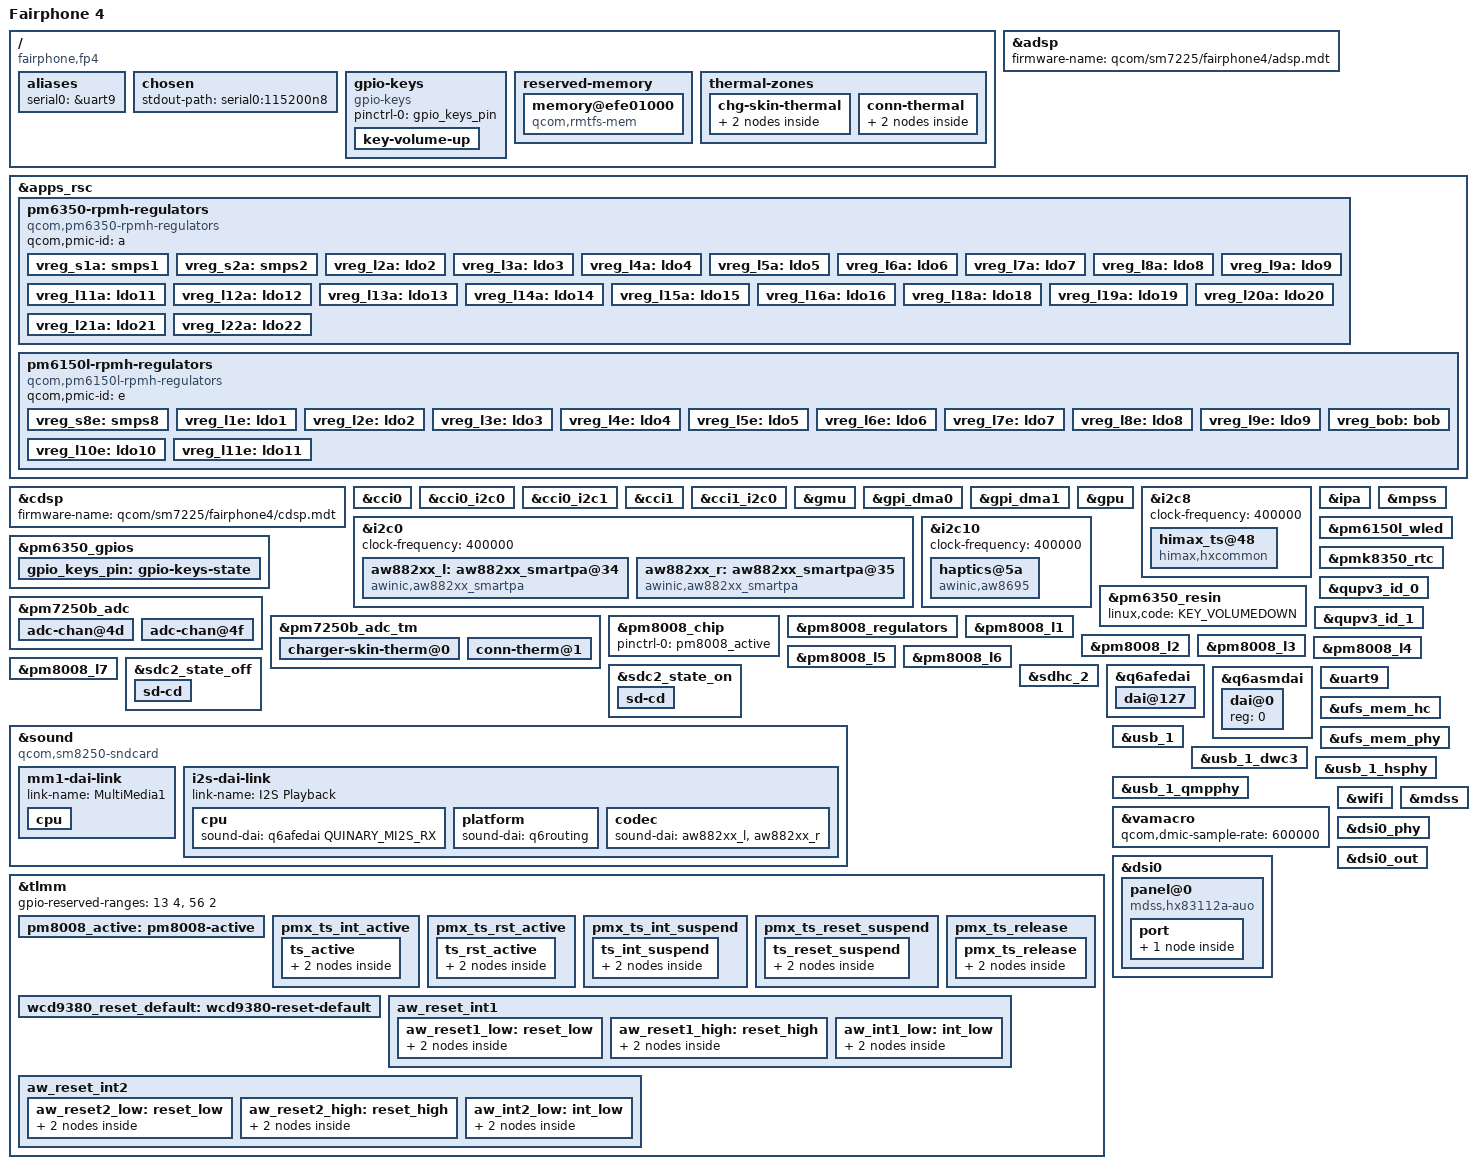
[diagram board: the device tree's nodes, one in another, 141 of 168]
// SPDX-License-Identifier: BSD-3-Clause
/*
 * Copyright (c) 2021, Luca Weiss <luca@z3ntu.xyz>
 */

/dts-v1/;

#include <dt-bindings/gpio/gpio.h>
#include <dt-bindings/input/input.h>
#include <dt-bindings/pinctrl/qcom,pmic-gpio.h>
#include <dt-bindings/regulator/qcom,rpmh-regulator.h>
#include <dt-bindings/sound/qcom,q6asm.h>
#include "sm7225.dtsi"
#include "pm6150l.dtsi"
#include "pm6350.dtsi"
#include "pm7250b.dtsi"
#include "pmk8350.dtsi"

/ {
	model = "Fairphone 4";
	compatible = "fairphone,fp4", "qcom,sm7225";
	chassis-type = "handset";

	/* required for bootloader to select correct board */
	qcom,msm-id = <434 0x10000>, <459 0x10000>;
	qcom,board-id = <8 32>;

	aliases {
		serial0 = &uart9;
	};

	chosen {
		#address-cells = <2>;
		#size-cells = <2>;
		ranges;

		stdout-path = "serial0:115200n8";
	};

#if 0
	wcd9380: codec {
		compatible = "qcom,wcd9380-codec";
		#sound-dai-cells = <1>;
		reset-gpios = <&tlmm 83 GPIO_ACTIVE_HIGH>;
		vdd-buck-supply = <&vreg_l14a>;
		vdd-rxtx-supply = <&vreg_l11a>;
		vdd-io-supply = <&vreg_l11a>;
		vdd-mic-bias-supply = <&vreg_bob>;
		qcom,micbias1-microvolt = <2700000>;
		qcom,micbias2-microvolt = <2700000>;
		qcom,micbias3-microvolt = <2700000>;
		qcom,micbias4-microvolt = <2700000>;
		//qcom,mbhc-buttons-vthreshold-microvolt = <75000 150000 237000 500000 500000 500000 500000 500000>;
		//qcom,mbhc-headset-vthreshold-microvolt = <1700000>;
		//qcom,mbhc-headphone-vthreshold-microvolt = <50000>;
		qcom,rx-device = <&wcd_rx>;
		qcom,tx-device = <&wcd_tx>;

		pinctrl-names = "default";
		pinctrl-0 = <&wcd9380_reset_default>;
	};
#endif

	gpio-keys {
		compatible = "gpio-keys";
		pinctrl-names = "default";
		pinctrl-0 = <&gpio_keys_pin>;

		key-volume-up {
			label = "volume_up";
			linux,code = <KEY_VOLUMEUP>;
			gpios = <&pm6350_gpios 2 GPIO_ACTIVE_LOW>;
		};
	};

	reserved-memory {
		/*
		 * The rmtfs memory region in downstream is 'dynamically allocated'
		 * but given the same address every time. Hard code it as this address is
		 * where the modem firmware expects it to be.
		 */
		memory@efe01000 {
			compatible = "qcom,rmtfs-mem";
			reg = <0 0xefe01000 0 0x600000>;
			no-map;

			qcom,client-id = <1>;
			qcom,vmid = <15>;
		};
	};

	thermal-zones {
		chg-skin-thermal {
			polling-delay-passive = <0>;
			polling-delay = <0>;
			thermal-sensors = <&pm7250b_adc_tm 0>;

			trips {
				active-config0 {
					temperature = <125000>;
					hysteresis = <1000>;
					type = "passive";
				};
			};
		};

		conn-thermal {
			polling-delay-passive = <0>;
			polling-delay = <0>;
			thermal-sensors = <&pm7250b_adc_tm 1>;

			trips {
				active-config0 {
					temperature = <125000>;
					hysteresis = <1000>;
					type = "passive";
				};
			};
		};
	};
};

&adsp {
	status = "okay";
	firmware-name = "qcom/sm7225/fairphone4/adsp.mdt";
};

&apps_rsc {
	pm6350-rpmh-regulators {
		compatible = "qcom,pm6350-rpmh-regulators";
		qcom,pmic-id = "a";

		vreg_s1a: smps1 {
			regulator-min-microvolt = <1000000>;
			regulator-max-microvolt = <1200000>;
		};

		vreg_s2a: smps2 {
			regulator-min-microvolt = <1503000>;
			regulator-max-microvolt = <2048000>;
		};

		vreg_l2a: ldo2 {
			regulator-min-microvolt = <1503000>;
			regulator-max-microvolt = <1980000>;
			regulator-initial-mode = <RPMH_REGULATOR_MODE_HPM>;
		};

		vreg_l3a: ldo3 {
			regulator-min-microvolt = <2700000>;
			regulator-max-microvolt = <3300000>;
			regulator-initial-mode = <RPMH_REGULATOR_MODE_HPM>;
		};

		vreg_l4a: ldo4 {
			regulator-min-microvolt = <352000>;
			regulator-max-microvolt = <801000>;
			regulator-initial-mode = <RPMH_REGULATOR_MODE_HPM>;
		};

		vreg_l5a: ldo5 {
			regulator-min-microvolt = <1503000>;
			regulator-max-microvolt = <1980000>;
			regulator-initial-mode = <RPMH_REGULATOR_MODE_HPM>;
		};

		vreg_l6a: ldo6 {
			regulator-min-microvolt = <1710000>;
			regulator-max-microvolt = <3544000>;
			regulator-initial-mode = <RPMH_REGULATOR_MODE_HPM>;
		};

		vreg_l7a: ldo7 {
			regulator-min-microvolt = <1620000>;
			regulator-max-microvolt = <1980000>;
			regulator-initial-mode = <RPMH_REGULATOR_MODE_HPM>;
		};

		vreg_l8a: ldo8 {
			regulator-min-microvolt = <2800000>;
			regulator-max-microvolt = <2800000>;
			regulator-initial-mode = <RPMH_REGULATOR_MODE_HPM>;
		};

		vreg_l9a: ldo9 {
			regulator-min-microvolt = <1650000>;
			regulator-max-microvolt = <3401000>;
			regulator-initial-mode = <RPMH_REGULATOR_MODE_HPM>;
		};

		vreg_l11a: ldo11 {
			regulator-min-microvolt = <1800000>;
			regulator-max-microvolt = <2000000>;
			regulator-initial-mode = <RPMH_REGULATOR_MODE_HPM>;
			regulator-always-on;
		};

		vreg_l12a: ldo12 {
			regulator-min-microvolt = <1620000>;
			regulator-max-microvolt = <1980000>;
			regulator-initial-mode = <RPMH_REGULATOR_MODE_HPM>;
		};

		vreg_l13a: ldo13 {
			regulator-min-microvolt = <570000>;
			regulator-max-microvolt = <650000>;
			regulator-initial-mode = <RPMH_REGULATOR_MODE_HPM>;
		};

		vreg_l14a: ldo14 {
			regulator-min-microvolt = <1700000>;
			regulator-max-microvolt = <1900000>;
			regulator-initial-mode = <RPMH_REGULATOR_MODE_HPM>;
		};

		vreg_l15a: ldo15 {
			regulator-min-microvolt = <1100000>;
			regulator-max-microvolt = <1305000>;
			regulator-initial-mode = <RPMH_REGULATOR_MODE_HPM>;
		};

		vreg_l16a: ldo16 {
			regulator-min-microvolt = <830000>;
			regulator-max-microvolt = <921000>;
			regulator-initial-mode = <RPMH_REGULATOR_MODE_HPM>;
		};

		vreg_l18a: ldo18 {
			regulator-min-microvolt = <788000>;
			regulator-max-microvolt = <1049000>;
			regulator-initial-mode = <RPMH_REGULATOR_MODE_HPM>;
		};

		vreg_l19a: ldo19 {
			regulator-min-microvolt = <1080000>;
			regulator-max-microvolt = <1305000>;
			regulator-initial-mode = <RPMH_REGULATOR_MODE_HPM>;
		};

		vreg_l20a: ldo20 {
			regulator-min-microvolt = <530000>;
			regulator-max-microvolt = <801000>;
			regulator-initial-mode = <RPMH_REGULATOR_MODE_HPM>;
		};

		vreg_l21a: ldo21 {
			regulator-min-microvolt = <751000>;
			regulator-max-microvolt = <825000>;
			regulator-initial-mode = <RPMH_REGULATOR_MODE_HPM>;
		};

		vreg_l22a: ldo22 {
			regulator-min-microvolt = <1080000>;
			regulator-max-microvolt = <1305000>;
			regulator-initial-mode = <RPMH_REGULATOR_MODE_HPM>;
		};
	};

	pm6150l-rpmh-regulators {
		compatible = "qcom,pm6150l-rpmh-regulators";
		qcom,pmic-id = "e";

		vreg_s8e: smps8 {
			regulator-min-microvolt = <313000>;
			regulator-max-microvolt = <1395000>;
		};

		vreg_l1e: ldo1 {
			regulator-min-microvolt = <1620000>;
			regulator-max-microvolt = <1980000>;
			regulator-initial-mode = <RPMH_REGULATOR_MODE_HPM>;
		};

		vreg_l2e: ldo2 {
			regulator-min-microvolt = <1170000>;
			regulator-max-microvolt = <1305000>;
			regulator-initial-mode = <RPMH_REGULATOR_MODE_HPM>;
		};

		vreg_l3e: ldo3 {
			regulator-min-microvolt = <1100000>;
			regulator-max-microvolt = <1299000>;
			regulator-initial-mode = <RPMH_REGULATOR_MODE_HPM>;
		};

		vreg_l4e: ldo4 {
			regulator-min-microvolt = <1620000>;
			regulator-max-microvolt = <3300000>;
			regulator-initial-mode = <RPMH_REGULATOR_MODE_HPM>;
		};

		vreg_l5e: ldo5 {
			regulator-min-microvolt = <1620000>;
			regulator-max-microvolt = <3300000>;
			regulator-initial-mode = <RPMH_REGULATOR_MODE_HPM>;
		};

		vreg_l6e: ldo6 {
			regulator-min-microvolt = <1700000>;
			regulator-max-microvolt = <3544000>;
			regulator-initial-mode = <RPMH_REGULATOR_MODE_HPM>;
		};

		vreg_l7e: ldo7 {
			regulator-min-microvolt = <2700000>;
			regulator-max-microvolt = <3544000>;
			regulator-initial-mode = <RPMH_REGULATOR_MODE_HPM>;
		};

		vreg_l8e: ldo8 {
			regulator-min-microvolt = <1620000>;
			regulator-max-microvolt = <2000000>;
			regulator-initial-mode = <RPMH_REGULATOR_MODE_HPM>;
		};

		vreg_l9e: ldo9 {
			regulator-min-microvolt = <2700000>;
			regulator-max-microvolt = <3544000>;
			regulator-initial-mode = <RPMH_REGULATOR_MODE_HPM>;
		};

		vreg_l10e: ldo10 {
			regulator-min-microvolt = <3000000>;
			regulator-max-microvolt = <3401000>;
			regulator-initial-mode = <RPMH_REGULATOR_MODE_HPM>;
		};

		vreg_l11e: ldo11 {
			regulator-min-microvolt = <3000000>;
			regulator-max-microvolt = <3401000>;
			regulator-initial-mode = <RPMH_REGULATOR_MODE_HPM>;
		};

		vreg_bob: bob {
			regulator-min-microvolt = <1620000>;
			regulator-max-microvolt = <5492000>;
			regulator-initial-mode = <RPMH_REGULATOR_MODE_AUTO>;
			regulator-allow-bypass;
		};
	};
};

&cdsp {
	status = "okay";
	firmware-name = "qcom/sm7225/fairphone4/cdsp.mdt";
};

&cci0 {
	status = "okay";
};

&cci0_i2c0 {
	/* IMX582 @ 0x1a */
};

&cci0_i2c1 {
	/* IMX582 @ 0x1a */
};

&cci1 {
	status = "okay";
};

&cci1_i2c0 {
	/* IMX576 @ 0x10 */
};

&gmu {
	status = "okay";
};

&gpi_dma0 {
	status = "okay";
};

&gpi_dma1 {
	status = "okay";
};

&gpu {
	status = "okay";
};

&i2c0 {
	status = "okay";
	clock-frequency = <400000>;

	aw882xx_l: aw882xx_smartpa@34 {
		compatible = "awinic,aw882xx_smartpa";
		reg = <0x34>;
		reset-gpio = <&tlmm 12 0>;
		irq-gpio = <&tlmm 48 0x2008>;
		monitor-flag = <1>;
		sync-flag = <0>;
		monitor-timer-val = <3000>;
		aw-cali-mode = "aw_misc";
		sound-channel = "left";
		aw-stereo-cali;
		status = "okay";
		pinctrl-names = "aw_reset_low",
			"aw_reset_high",
			"aw_irq_active";
		pinctrl-0 = <&aw_reset1_low>;
		pinctrl-1 = <&aw_reset1_high>;
		pinctrl-2 = <&aw_int1_low>;
		#sound-dai-cells = <0>;
	};

	aw882xx_r: aw882xx_smartpa@35 {
		compatible = "awinic,aw882xx_smartpa";
		reg = <0x35>;
		reset-gpio = <&tlmm 47 0>;
		irq-gpio = <&tlmm 11 0x2008>;
		monitor-flag = <1>;
		sync-flag = <0>;
		monitor-timer-val = <3000>;
		aw-cali-mode = "aw_misc";
		sound-channel = "right";
		aw-stereo-cali;
		status = "okay";
		pinctrl-names = "aw_reset_low",
			"aw_reset_high",
			"aw_irq_active";
		pinctrl-0 = <&aw_reset2_low>;
		pinctrl-1 = <&aw_reset2_high>;
		pinctrl-2 = <&aw_int2_low>;
		#sound-dai-cells = <0>;
	};
};

&i2c8 {
	status = "okay";
	clock-frequency = <400000>;

	himax_ts@48 {
		compatible = "himax,hxcommon";
		reg = <0x48>;
		interrupt-parent = <&tlmm>;
		interrupts = <22 0x2>;
		pinctrl-names = "pmx_ts_active","pmx_ts_suspend",
			"pmx_ts_release";
		pinctrl-0 = <&ts_active &ts_rst_active>;
		pinctrl-1 = <&ts_int_suspend &ts_reset_suspend>;
		pinctrl-2 = <&pmx_ts_release>;
		himax,panel-coords = <0 1080 0 2340>;
		himax,display-coords = <0 1080 0 2340>;
		himax,irq-gpio = <&tlmm 22 0x00>;
		himax,rst-gpio = <&tlmm 21 0x00>;
		report_type = <1>;

		//panel = <&dsi_hx83112a_auo_1080_video>;
	};
};

&i2c10 {
	status = "okay";
	clock-frequency = <400000>;

	#include "pm8008.dtsi"

	haptics@5a {
		compatible = "awinic,aw8695";
		reg = <0x5a>;
		interrupts-extended = <&tlmm 85 IRQ_TYPE_EDGE_FALLING>;
		reset-gpios = <&tlmm 90 GPIO_ACTIVE_HIGH>;

		awinic,f0-preset = <2350>;
		awinic,f0-coefficient = <260>;
		awinic,f0-calibration-percent = <7>;
		awinic,drive-level = <125>;

		awinic,f0-detection-play-time = <5>;
		awinic,f0-detection-wait-time = <3>;
		awinic,f0-detection-repeat = <2>;
		awinic,f0-detection-trace = <15>;

		awinic,boost-debug = /bits/ 8 <0x30 0xeb 0xd4>;
		awinic,tset = /bits/ 8 <0x12>;
		awinic,r-spare = /bits/ 8 <0x68>;

		awinic,bemf-upper-threshold = <4104>;
		awinic,bemf-lower-threshold = <1016>;
	};
};

&ipa {
	status = "okay";

	memory-region = <&pil_ipa_fw_mem>;
	firmware-name = "qcom/sm7225/fairphone4/ipa_fws.mdt";
};

&mpss {
	status = "okay";
	firmware-name = "qcom/sm7225/fairphone4/modem.mdt";
};

&pm6150l_wled {
	status = "okay";

	qcom,switching-freq = <800>;
	qcom,current-limit-microamp = <20000>;
	qcom,num-strings = <2>;
};

&pm6350_gpios {
	gpio_keys_pin: gpio-keys-state {
		pins = "gpio2";
		function = PMIC_GPIO_FUNC_NORMAL;
		bias-pull-up;
		input-enable;
		power-source = <0>;
	};
};

&pm6350_resin {
	status = "okay";
	linux,code = <KEY_VOLUMEDOWN>;
};

&pm7250b_adc {
	adc-chan@4d {
		reg = <ADC5_AMUX_THM1_100K_PU>;
		qcom,ratiometric;
		qcom,hw-settle-time = <200>;
		qcom,pre-scaling = <1 1>;
		label = "charger_skin_therm";
	};

	adc-chan@4f {
		reg = <ADC5_AMUX_THM3_100K_PU>;
		qcom,ratiometric;
		qcom,hw-settle-time = <200>;
		qcom,pre-scaling = <1 1>;
		label = "conn_therm";
	};
};

&pm7250b_adc_tm {
	status = "okay";

	charger-skin-therm@0 {
		reg = <0>;
		io-channels = <&pm7250b_adc ADC5_AMUX_THM1_100K_PU>;
		qcom,ratiometric;
		qcom,hw-settle-time-us = <200>;
	};

	conn-therm@1 {
		reg = <1>;
		io-channels = <&pm7250b_adc ADC5_AMUX_THM3_100K_PU>;
		qcom,ratiometric;
		qcom,hw-settle-time-us = <200>;
	};
};

&pmk8350_rtc {
	status = "okay";
};

&qupv3_id_0 {
	status = "okay";
};

&qupv3_id_1 {
	status = "okay";
};

&pm8008_chip {
	pinctrl-names = "default";
	pinctrl-0 = <&pm8008_active>;
};

&pm8008_regulators {
	vdd_l1_l2-supply = <&vreg_s8e>;
	vdd_l3_l4-supply = <&vreg_bob>;
	vdd_l5-supply = <&vreg_bob>;
	vdd_l6-supply = <&vreg_s2a>;
	vdd_l7-supply = <&vreg_bob>;
};

&pm8008_l1 {
	regulator-min-microvolt = <528000>;
	regulator-max-microvolt = <1200000>;
	regulator-min-dropout-voltage-microvolt = <110000>;
};

&pm8008_l2 {
	regulator-min-microvolt = <528000>;
	regulator-max-microvolt = <1200000>;
	regulator-min-dropout-voltage-microvolt = <110000>;
};

&pm8008_l3 {
	regulator-min-microvolt = <1500000>;
	regulator-max-microvolt = <2800000>;
	regulator-min-dropout-voltage-microvolt = <128000>;
};

&pm8008_l4 {
	regulator-min-microvolt = <1500000>;
	regulator-max-microvolt = <2904000>;
	regulator-min-dropout-voltage-microvolt = <96000>;
};

&pm8008_l5 {
	regulator-min-microvolt = <1500000>;
	regulator-max-microvolt = <2900000>;
	regulator-min-dropout-voltage-microvolt = <128000>;
};

&pm8008_l6 {
	regulator-min-microvolt = <1500000>;
	regulator-max-microvolt = <1800000>;
	regulator-min-dropout-voltage-microvolt = <56000>;
};

&pm8008_l7 {
	regulator-min-microvolt = <1500000>;
	regulator-max-microvolt = <3140000>;
	regulator-min-dropout-voltage-microvolt = <120000>;
};

&sdc2_state_off {
	sd-cd {
		pins = "gpio94";
		function = "gpio";
		drive-strength = <2>;
		bias-disable;
	};
};

&sdc2_state_on {
	sd-cd {
		pins = "gpio94";
		function = "gpio";
		drive-strength = <2>;
		bias-pull-up;
	};
};

&sdhc_2 {
	status = "okay";

	cd-gpios = <&tlmm 94 GPIO_ACTIVE_LOW>;

	vmmc-supply = <&vreg_l9e>;
	vqmmc-supply = <&vreg_l6e>;
};

#define ENABLE_ECHO_REFERENCE 0

&q6afedai {
	// RX = playback?
	dai@127 {
		reg = <QUINARY_MI2S_RX>;
		// gpio135 is used (first data line of quinary i2s)
		qcom,sd-lines = <0>; // dai_mi2s4: qcom,msm-mi2s-rx-lines = <1>;
	};

#if ENABLE_ECHO_REFERENCE
	// TX = record?
	dai@128 {
		reg = <QUINARY_MI2S_TX>;
		// gpio136 is used (second data line of quinary i2s)
		qcom,sd-lines = <1>; // qcom,msm-mi2s-tx-lines = <2>;
	};
#endif
};

&q6asmdai {
	dai@0 {
		reg = <0>;
	};

#if ENABLE_ECHO_REFERENCE
	dai@1 {
		reg = <1>;
	};
#endif
};

&sound {
	compatible = "qcom,sm8250-sndcard"; // FIXME
	pinctrl-0 = <&i2s1_active>;
	pinctrl-names = "default";
	model = "Fairphone 4";

	mm1-dai-link {
		link-name = "MultiMedia1";
		cpu {
			sound-dai = <&q6asmdai MSM_FRONTEND_DAI_MULTIMEDIA1>;
		};
	};

#if ENABLE_ECHO_REFERENCE
	mm2-dai-link {
		link-name = "MultiMedia2";
		cpu {
			sound-dai = <&q6asmdai MSM_FRONTEND_DAI_MULTIMEDIA2>;
		};
	};

	mm3-dai-link {
		link-name = "MultiMedia3";
		cpu {
			sound-dai = <&q6asmdai MSM_FRONTEND_DAI_MULTIMEDIA3>;
		};
	};
#endif

#if 0
	// TODO Only used by HAC?
	wcd-playback-dai-link {
		link-name = "WCD Playback";
		cpu {
			sound-dai = <&q6afedai RX_CODEC_DMA_RX_0>;
		};
		codec {
			sound-dai = <&wcd9380 0>, <&swr1 0>, <&rxmacro 0>;
		};
		platform {
			sound-dai = <&q6routing>;
		};
	};
#endif

#if 0
	// Microphone
	wcd-capture-dai-link {
		link-name = "WCD Capture";
		cpu {
			sound-dai = <&q6afedai TX_CODEC_DMA_TX_3>;
		};

		codec {
			sound-dai = <&wcd9380 1>, <&swr2 0>, <&txmacro 0>;
		};
		platform {
			sound-dai = <&q6routing>;
		};
	};
#endif

	i2s-dai-link {
		link-name = "I2S Playback";
		cpu {
			// From my understanding, the playback path to the amplifier is via GPIO135 / QUINARY_MI2S_RX.
			// The amplifier also returns the audio (I2STXEN) via GPIO136 / QUINARY_MI2S_TX for echo-reference.
			sound-dai = <&q6afedai QUINARY_MI2S_RX>;
		};

		platform {
			sound-dai = <&q6routing>;
		};

		codec {
			sound-dai = <&aw882xx_l>, <&aw882xx_r>;
		};
	};

#if ENABLE_ECHO_REFERENCE
	i2s-dai-link {
		link-name = "I2S Capture"; // just echo reference?
		cpu {
			// From my understanding, the playback path to the amplifier is via GPIO135 / QUINARY_MI2S_RX.
			// The amplifier also returns the audio (I2STXEN) via GPIO136 / QUINARY_MI2S_TX for echo-reference.
			sound-dai = <&q6afedai QUINARY_MI2S_TX>;
		};

		platform {
			sound-dai = <&q6routing>;
		};

		codec {
			//sound-dai = <&aw882xx_l>, <&aw882xx_r>; // TODO how to get both amps connected?
			//sound-dai = <&aw882xx_l>;
			sound-dai = <&aw882xx_r>;
		};
	};
#endif

#if 0
	wsa-dai-link {
		link-name = "WSA Playback";
		cpu {
			sound-dai = <&q6afedai WSA_CODEC_DMA_RX_0>;
		};

		codec {
			sound-dai = <&left_spkr>, <&right_spkr>, <&swr0 0>, <&wsamacro 0>;
		};
		platform {
			sound-dai = <&q6routing>;
		};
	};
#endif

#if 0
	va-dai-link {
		link-name = "VA Capture";
		cpu {
			sound-dai = <&q6afedai VA_CODEC_DMA_TX_0>;
		};

		platform {
			sound-dai = <&q6routing>;
		};

		codec {
			sound-dai = <&vamacro 0>;
		};
	};
#endif
};

#if 0
&swr1 {
	wcd_rx: wcd9380-rx@0,4 {
		compatible = "sdw20217010d00";
		reg = <0 4>;
		qcom,rx-port-mapping = <1 2 3 4 5>;
	};
};

&swr2 {
	wcd_tx: wcd9380-tx@0,3 {
		compatible = "sdw20217010d00";
		reg = <0 3>;
		qcom,tx-port-mapping = <2 3 4 5>;
	};
};
#endif

&tlmm {
	gpio-reserved-ranges = <13 4>, <56 2>;

	pm8008_active: pm8008-active {
		pins = "gpio58";
		function = "gpio";
		bias-disable;
		output-high;
	};

	pmx_ts_int_active {
		ts_active: ts_active {
			mux {
				pins = "gpio22";
				function = "gpio";
			};

			config {
				pins = "gpio22";
				drive-strength = <8>;
				bias-pull-up;
			};
		};
	};

	pmx_ts_rst_active {
		ts_rst_active: ts_rst_active {
			mux {
				pins = "gpio21";
				function = "gpio";
			};

			config {
				pins = "gpio21";
				drive-strength = <8>;
				bias-pull-up;
				output-high;
			};
		};
	};

	pmx_ts_int_suspend {
		ts_int_suspend: ts_int_suspend {
			mux {
				pins = "gpio22";
				function = "gpio";
			};

			config {
				pins = "gpio22";
				drive-strength = <2>;
				bias-pull-down;
			};
		};
	};

	pmx_ts_reset_suspend {
		ts_reset_suspend: ts_reset_suspend {
			mux {
				pins = "gpio21";
				function = "gpio";
			};

			config {
				pins = "gpio21";
				drive-strength = <2>;
				bias-pull-down;
				output-low;
			};
		};
	};

	pmx_ts_release {
		pmx_ts_release: pmx_ts_release {
			mux {
				pins = "gpio21", "gpio22";
				function = "gpio";
			};

			config {
				pins = "gpio21", "gpio22";
				drive-strength = <2>;
				bias-disable;
			};
		};
	};

	wcd9380_reset_default: wcd9380-reset-default {
		pins = "gpio83";
		function = "gpio";
		drive-strength = <16>;
		//output-high;
	};

	aw_reset_int1 {
		aw_reset1_low: reset_low {
			mux {
				pins = "gpio12";
				function = "gpio";
			};
			config {
				pins = "gpio12";
				drive-strength = <2>;
				bias-disable;
				output-low;
			};
		};
		aw_reset1_high: reset_high {
			mux {
				pins = "gpio12";
				function = "gpio";
			};
			config {
				pins = "gpio12";
				drive-strength = <2>;
				bias-disable;
				output-high;
			};
		};
		aw_int1_low: int_low {
			mux {
				pins = "gpio48";
				function = "gpio";
			};
			config {
				pins = "gpio48";
				drive-strength = <2>;
				bias-pull-down;
				input-enable;
			};
		};
	};

	aw_reset_int2 {
		aw_reset2_low: reset_low {
			mux {
				pins = "gpio47";
				function = "gpio";
			};
			config {
				pins = "gpio47";
				drive-strength = <2>;
				bias-disable;
				output-low;
			};
		};
		aw_reset2_high: reset_high {
			mux {
				pins = "gpio47";
				function = "gpio";
			};
			config {
				pins = "gpio47";
				drive-strength = <2>;
				bias-disable;
				output-high;
			};
		};
		aw_int2_low: int_low {
			mux {
				pins = "gpio11";
				function = "gpio";
			};
			config {
				pins = "gpio11";
				drive-strength = <2>;
				bias-pull-down;
				input-enable;
			};
		};
	};
};

&uart9 {
	status = "okay";
};

&ufs_mem_hc {
	status = "okay";

	reset-gpios = <&tlmm 156 GPIO_ACTIVE_LOW>;

	vcc-supply = <&vreg_l7e>;
	vcc-max-microamp = <800000>;
	vccq2-supply = <&vreg_l12a>;
	vccq2-max-microamp = <800000>;
};

&ufs_mem_phy {
	status = "okay";

	vdda-phy-supply = <&vreg_l18a>;
	vdda-pll-supply = <&vreg_l22a>;
};

&usb_1 {
	status = "okay";
};

&usb_1_dwc3 {
	maximum-speed = "super-speed";
	dr_mode = "peripheral";
};

&usb_1_hsphy {
	status = "okay";

	vdd-supply = <&vreg_l18a>;
	vdda-pll-supply = <&vreg_l2a>;
	vdda-phy-dpdm-supply = <&vreg_l3a>;
};

&usb_1_qmpphy {
	status = "okay";

	vdda-phy-supply = <&vreg_l22a>;
	vdda-pll-supply = <&vreg_l16a>;
};

&vamacro {
	//pinctrl-0 = <&dmic01_active>;
	//pinctrl-names = "default";
	qcom,dmic-sample-rate = <600000>;
};

&wifi {
	status = "okay";

	vdd-0.8-cx-mx-supply = <&vreg_l4a>;
	vdd-1.8-xo-supply = <&vreg_l7a>;
	vdd-1.3-rfa-supply = <&vreg_l2e>;
	vdd-3.3-ch0-supply = <&vreg_l10e>;
	vdd-3.3-ch1-supply = <&vreg_l11e>;
};

&mdss {
	status = "okay";
};

&dsi0 {
	status = "okay";

	panel@0 {
		compatible = "mdss,hx83112a-auo";
		reg = <0>;

		backlight = <&pm6150l_wled>;
		reset-gpios = <&pm6150l_gpio 9 GPIO_ACTIVE_LOW>;

		port {
			panel_in: endpoint {
				remote-endpoint = <&dsi0_out>;
			};
		};
	};
};

&dsi0_phy {
	status = "okay";
};

&dsi0_out {
	data-lanes = <0 1 2 3>;
	remote-endpoint = <&panel_in>;
};
